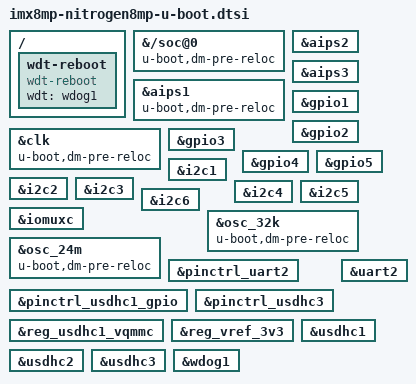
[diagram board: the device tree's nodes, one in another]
// SPDX-License-Identifier: GPL-2.0+
/*
 * Copyright 2019 NXP
 */

/ {
	wdt-reboot {
		compatible = "wdt-reboot";
		wdt = <&wdog1>;
		u-boot,dm-spl;
	};
};

&{/soc@0} {
	u-boot,dm-pre-reloc;
	u-boot,dm-spl;
};

&aips1 {
	u-boot,dm-spl;
	u-boot,dm-pre-reloc;
};

&aips2 {
	u-boot,dm-spl;
};

&aips3 {
	u-boot,dm-spl;
};

&clk {
	u-boot,dm-spl;
	u-boot,dm-pre-reloc;
};

&gpio1 {
	u-boot,dm-spl;
};

&gpio2 {
	u-boot,dm-spl;
};

&gpio3 {
	u-boot,dm-spl;
};

&gpio4 {
	u-boot,dm-spl;
};

&gpio5 {
	u-boot,dm-spl;
};

&i2c1 {
	u-boot,dm-spl;
};

&i2c2 {
	u-boot,dm-spl;
};

&i2c3 {
	u-boot,dm-spl;
};

&i2c4 {
	u-boot,dm-spl;
};

&i2c5 {
	u-boot,dm-spl;
};

&i2c6 {
	u-boot,dm-spl;
};

&iomuxc {
	u-boot,dm-spl;
};

&osc_32k {
	u-boot,dm-spl;
	u-boot,dm-pre-reloc;
};

&osc_24m {
	u-boot,dm-spl;
	u-boot,dm-pre-reloc;
};

&pinctrl_uart2 {
	u-boot,dm-spl;
};

&pinctrl_usdhc1_gpio {
	u-boot,dm-spl;
};

&pinctrl_usdhc3 {
	u-boot,dm-spl;
};

&reg_usdhc1_vqmmc {
	u-boot,dm-spl;
};

&reg_vref_3v3 {
	u-boot,dm-spl;
};

&uart2 {
	u-boot,dm-spl;
};

&usdhc1 {
	u-boot,dm-spl;
};

&usdhc2 {
	u-boot,dm-spl;
};

&usdhc3 {
	u-boot,dm-spl;
};

&wdog1 {
	u-boot,dm-spl;
};
